AUTOSAR XML (schema 4-2-2)
package /Components
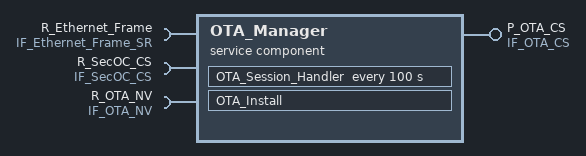
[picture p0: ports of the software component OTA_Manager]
  service sw component type OTA_Manager
    provide port P_OTA_CS: provided-interface=IF_OTA_CS
    require port R_Ethernet_Frame: required-interface=IF_Ethernet_Frame_SR
    require port R_SecOC_CS: required-interface=IF_SecOC_CS
    require port R_OTA_NV: required-interface=IF_OTA_NV
    behavior OTA_Manager_InternalBehavior
      init event OTA_InitEvent: start-on-event=OTA_Session_Handler
      timing event OTA_SessionCyclic: start-on-event=OTA_Session_Handler, period=100
      runnable OTA_Session_Handler: minimum-start-interval=10
        data-read-access:
          access Read_Link_Status: accessed-variable={autosar-variable-in-impl-datatype={port-prototype=R_Ethernet_Frame, target-data-prototype=link_status_impl}, autosar-variable=R_Ethernet_Frame.link_status}
        data-receive-point-by-values:
          access RX_Ethernet_Frame: accessed-variable={autosar-variable-in-impl-datatype={port-prototype=R_Ethernet_Frame, target-data-prototype=ethernet_frame_impl}, autosar-variable=R_Ethernet_Frame.ethernet_frame}
        data-write-access:
          access NV_Write_Metadata: accessed-variable={autosar-variable-in-impl-datatype={port-prototype=R_OTA_NV, target-data-prototype=ota_metadata_block_impl}, autosar-variable=R_OTA_NV.ota_metadata_block}
          access NV_Write_ImageHash: accessed-variable={autosar-variable-in-impl-datatype={port-prototype=R_OTA_NV, target-data-prototype=image_hash_impl}, autosar-variable=R_OTA_NV.image_hash}
        sync call SecOC_Verify_Sync: operation=R_SecOC_CS.Verify_Auth_Tag_Op, timeout=5
      runnable OTA_Install: minimum-start-interval=100
        data-read-access:
          access Read_Image_Hash: accessed-variable={autosar-variable-in-impl-datatype={port-prototype=R_OTA_NV, target-data-prototype=image_hash_impl}, autosar-variable=R_OTA_NV.image_hash}
          access Read_Partition_Map: accessed-variable={autosar-variable-in-impl-datatype={port-prototype=R_OTA_NV, target-data-prototype=partition_map_impl}, autosar-variable=R_OTA_NV.partition_map}
        data-receive-point-by-values:
          access RX_NV_InstallStatus: accessed-variable={autosar-variable-in-impl-datatype={port-prototype=R_OTA_NV, target-data-prototype=install_status_impl}, autosar-variable=R_OTA_NV.install_status}
        data-write-access:
          access NV_Update_InstallStatus: accessed-variable={autosar-variable-in-impl-datatype={port-prototype=R_OTA_NV, target-data-prototype=install_status_impl}, autosar-variable=R_OTA_NV.install_status}
        async call SecOC_RotateKey_Async: operation=R_SecOC_CS.Rotate_Key_Op, timeout=5
        sync call SecOC_Generate_Sync: operation=R_SecOC_CS.Generate_Auth_Tag_Op, timeout=2
